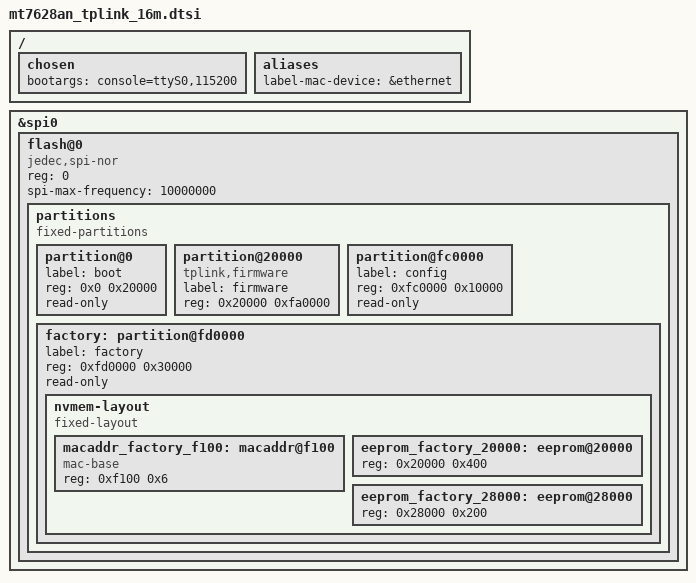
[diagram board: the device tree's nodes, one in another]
// SPDX-License-Identifier: GPL-2.0-or-later OR MIT

#include "mt7628an.dtsi"

#include <dt-bindings/input/input.h>
#include <dt-bindings/gpio/gpio.h>

/ {
	chosen {
		bootargs = "console=ttyS0,115200";
	};

	aliases {
		label-mac-device = &ethernet;
	};
};

&spi0 {
	status = "okay";

	flash@0 {
		compatible = "jedec,spi-nor";
		reg = <0>;
		spi-max-frequency = <10000000>;

		partitions {
			compatible = "fixed-partitions";
			#address-cells = <1>;
			#size-cells = <1>;

			partition@0 {
				label = "boot";
				reg = <0x0 0x20000>;
				read-only;
			};

			partition@20000 {
				compatible = "tplink,firmware";
				label = "firmware";
				reg = <0x20000 0xfa0000>;
			};

			partition@fc0000 {
				label = "config";
				reg = <0xfc0000 0x10000>;
				read-only;
			};

			factory: partition@fd0000 {
				label = "factory";
				reg = <0xfd0000 0x30000>;
				read-only;

				nvmem-layout {
					compatible = "fixed-layout";
					#address-cells = <1>;
					#size-cells = <1>;

					macaddr_factory_f100: macaddr@f100 {
						compatible = "mac-base";
						reg = <0xf100 0x6>;
						#nvmem-cell-cells = <1>;
					};

					eeprom_factory_20000: eeprom@20000 {
						reg = <0x20000 0x400>;
					};

					eeprom_factory_28000: eeprom@28000 {
						reg = <0x28000 0x200>;
					};
				};
			};
		};
	};
};
